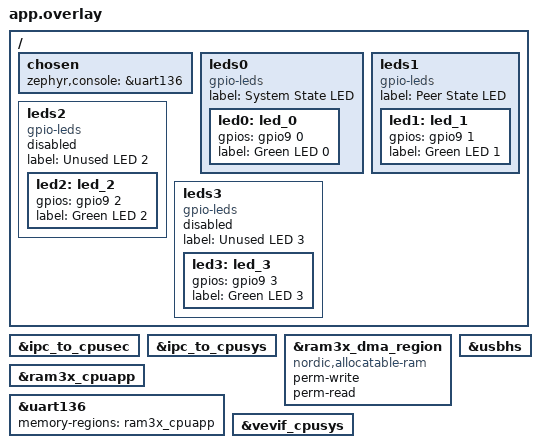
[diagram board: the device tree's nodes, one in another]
/*
 * Copyright (c) 2023 Nordic Semiconductor ASA
 *
 * SPDX-License-Identifier: LicenseRef-Nordic-5-Clause
 */

#include "nrf54h20dk_cpuapp_memory_map.dtsi"

/ {
	chosen {
		zephyr,console = &uart136;
	};

	/* Redefine leds to fit CAF requirements. */
	/delete-node/ leds;

	leds0 {
		compatible = "gpio-leds";
		status = "okay";
		label = "System State LED";

		led0: led_0 {
			gpios = < &gpio9 0 GPIO_ACTIVE_HIGH >;
			label = "Green LED 0";
		};
	};

	leds1 {
		compatible = "gpio-leds";
                status = "okay";
                label = "Peer State LED";

		led1: led_1 {
			gpios = < &gpio9 1 GPIO_ACTIVE_HIGH >;
			label = "Green LED 1";
		};
	};

        leds2 {
		compatible = "gpio-leds";
		status = "disabled";
		label = "Unused LED 2";

		led2: led_2 {
			gpios = < &gpio9 2 GPIO_ACTIVE_HIGH >;
			label = "Green LED 2";
		};
	};

	leds3 {
		compatible = "gpio-leds";
		status = "disabled";
		label = "Unused LED 3";

                led3: led_3 {
			gpios = < &gpio9 3 GPIO_ACTIVE_HIGH >;
			label = "Green LED 3";
		};
	};
};

/* The application core communicates with the secure domain to perform
 * the SUIT DFU. */
&ipc_to_cpusec {
	status = "okay";
};

/* The application core communicates with the system controller
 * through the NRFS service regarding USBHS peripheral. */
&ipc_to_cpusys {
	status = "okay";
};

/* Configure permission of RAM3X DMA node used by App core UART driver. */
&ram3x_dma_region {
	compatible = "nordic,allocatable-ram";
	perm-write;
	perm-read;
};

/* Enable RAM3X DMA CPUAPP subnode used by App core UART driver. */
&ram3x_cpuapp {
	status = "okay";
};

/* Configure App core UART. */
&uart136 {
	status = "okay";
	memory-regions = <&ram3x_cpuapp>;
};

&vevif_cpusys {
	status = "okay";
};

/* Configure App core USBHS. */
zephyr_udc0: &usbhs {
	status = "okay";
};
